# MSPM0C110X register map
Vendor: Texas Instruments; File version: This preliminary header file does not have a version number - build date: 2024-04-30 10:45:50
CPU: CM0 r0p1, little endian, MPU, no FPU, 3 interrupt priority bits
Registers are 32-bit, read-write, reset 0x0 unless marked. A register's access mark holds for its fields unless they carry their own. Offsets are from the block's base; [hi:lo] are bit positions; lines under a group give offsets from that group; {n}, {i} and the like mark numbered series; 'fields as' and 'values as' point back to an identical list; <NAME> marks a mode.

## SYSCTL
Base 0x400AF000
{0x4+0x18*i} SYSCTL_PINCM[{i}] (i=0..0) group
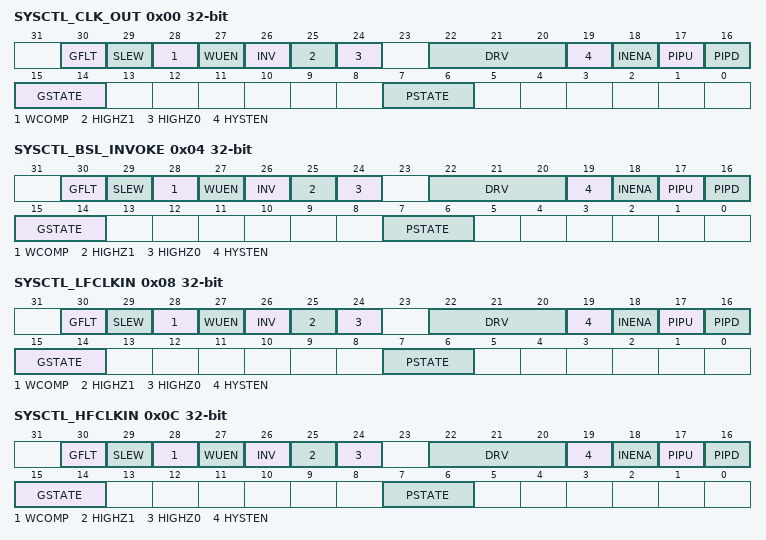
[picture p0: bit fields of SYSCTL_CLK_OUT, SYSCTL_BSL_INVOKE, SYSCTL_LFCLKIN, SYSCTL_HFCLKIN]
  0x00 SYSCTL_CLK_OUT — CLK_OUT
    [30] GFLT — Glitch Filter Enable
      0=DISABLE (No internal glitch filter); 1=ENABLE (Use internal glitch filter)
    [29] SLEW — Reserved Slew Rate Control
      0=DISABLE (No Slew Rate Control); 1=ENABLE (Use Slew Rate Control)
    [28] WCOMP — Wake up compare value
      0=MATCH_ZERO (Match 0 will wake); 1=MATCH_ONE (Match 1 will wake)
    [27] WUEN — Wake up enable
      0=NO_WAKEUP (Wake up not enabled); 1=WAKEUP (Wake up enabled)
    [26] INV — Invert digital input/output relative to peripheral/GPIO
      0=NO_CHNG (Input and output are non-inverted); 1=CHNG (Input and output are inverted)
    [25] HIGHZ1 — High-Z instead of high output
      0=DRV_HIGH (Pin can be driven high); 1=DRV_HIZ (Pin is tri-stated instead of driven high)
    [24] HIGHZ0 — High-Z instead of low output
      0=DRV_LOW (Pin can be driven low); 1=DRV_HIZ (Pin is tri-stated instead of driven low)
    [22:20] DRV — Drive strength options
      0=STRENGTH_0 (Lowest drive strength); {v}=STRENGTH_{v} (Drive strength {v+1}/8) (v=1..6); 7=STRENGTH_7 (Highest drive strength)
    [19] HYSTEN — Hysteresis enable
      0=DIS_HYST (No hysteresis); 1=EN_HYST (Hysteresis on)
    [18] INENA — Input enable
      0=INP_DISABLE (Inputs 0 to connected core); 1=INP_ENABLE (Inputs IO pad value to connected core)
    [17] PIPU — Pull up enable
      0=NO_PULL_UP; 1=PULL_UP
    [16] PIPD — Pull down enable
      0=NO_PULL_DOWN; 1=PULL_DOWN
    [15:14] GSTATE — GPIO Channel State
      0=UNASSIGNED (G-Channel is in Unassigned State); 1=HANDOVER (G-Channel is in Handover State); 2=CONC_NOT_LOCKED (G-Channel is in Connected State and not Locked (That is F field is allowed to change without going back through Unassigned state)); 3=CONC_LOCKED (G-Channel is in Connected State and Locked (That is F field is not allowed to change to a different non-Zero value until both G and P channels go to Unassigned))
    [7:6] PSTATE — Peripheral-Analog Channel State
      0=UNASSIGNED (P-Channel is in Unassigned State); 1=HANDOVER (P-Channel is in Handover State); 2=CONC_NOT_LOCKED (P-Channel is in Connected State and not Locked (That is F field is allowed to change without going back through Unassigned state)); 3=CONC_LOCKED (P-Channel is in Connected State and Locked (That is F field is not allowed to change to a different non-Zero value until both G and P channels go to Unassigned))
  0x04 SYSCTL_BSL_INVOKE — BSL Invoke
    fields as SYSCTL_PINCM[0].SYSCTL_CLK_OUT
  0x08 SYSCTL_LFCLKIN — BSL Invoke
    fields as SYSCTL_PINCM[0].SYSCTL_CLK_OUT
  0x0C SYSCTL_HFCLKIN — BSL Invoke
    fields as SYSCTL_PINCM[0].SYSCTL_CLK_OUT
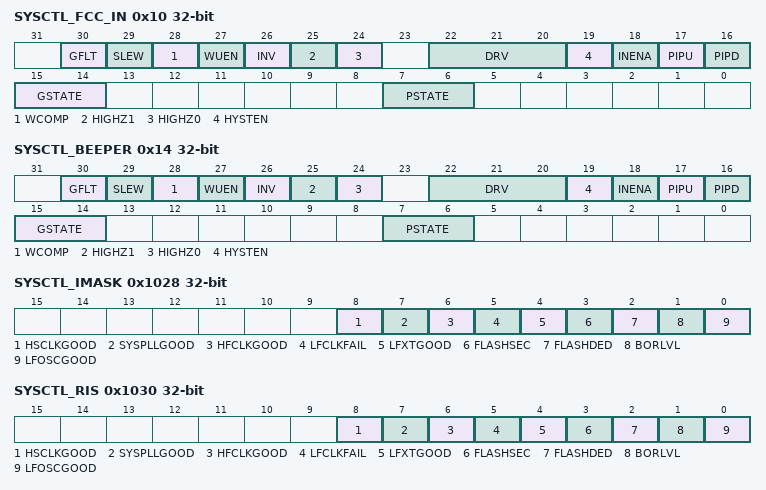
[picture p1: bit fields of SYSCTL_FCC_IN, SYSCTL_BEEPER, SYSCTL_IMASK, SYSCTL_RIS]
  0x10 SYSCTL_FCC_IN — BSL Invoke
    fields as SYSCTL_PINCM[0].SYSCTL_CLK_OUT
  0x14 SYSCTL_BEEPER — BEEPER
    fields as SYSCTL_PINCM[0].SYSCTL_CLK_OUT
0x1020 SYSCTL_IIDX ro — Event IIDX
  [3:0] STAT — Interrupt Index Register -- Read Only
    0=NO_INTR (No Interrupt); 1=LFOSCGOOD; 2=BORLVL; 3=FLASHDED; 4=FLASHSEC; 5=LFXTGOOD; 6=LFCLKFAIL; 7=HFCLKGOOD; 8=SYSPLLGOOD; 9=HSCLKGOOD
0x1028 SYSCTL_IMASK — Event IMASK
  [all] fields
    0=DISABLE; 1=ENABLE
  [8] HSCLKGOOD
  [7] SYSPLLGOOD
  [6] HFCLKGOOD
  [5] LFCLKFAIL — LFXT-EXLF Monitor Fail
  [4] LFXTGOOD
  [3] FLASHSEC — Flash Single Error Correct
  [2] FLASHDED — Flash Double Error Detect
  [1] BORLVL — BOR Level Indicator
  [0] LFOSCGOOD
0x1030 SYSCTL_RIS ro — Event RIS
  [all] fields
    0=FALSE; 1=TRUE
  [8] HSCLKGOOD
  [7] SYSPLLGOOD
  [6] HFCLKGOOD
  [5] LFCLKFAIL — LFXT-EXLF Monitor Fail
  [4] LFXTGOOD
  [3] FLASHSEC — Flash Single Error Correct
  [2] FLASHDED — Flash Double Error Detect
  [1] BORLVL — BOR Level Indicator
  [0] LFOSCGOOD
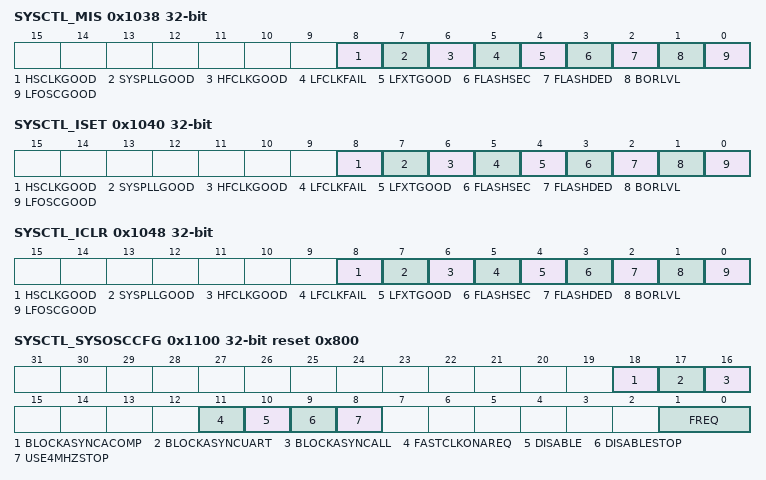
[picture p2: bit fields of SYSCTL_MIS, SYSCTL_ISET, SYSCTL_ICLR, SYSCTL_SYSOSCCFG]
0x1038 SYSCTL_MIS ro — Event MIS
  fields as SYSCTL_RIS
0x1040 SYSCTL_ISET wo — Event ISET
  [all] fields
    0=NO_EFFECT; 1=SET
  [8] HSCLKGOOD
  [7] SYSPLLGOOD
  [6] HFCLKGOOD
  [5] LFCLKFAIL — LFXT-EXLF Monitor Fail
  [4] LFXTGOOD
  [3] FLASHSEC — Flash Single Error Correct
  [2] FLASHDED — Flash Double Error Detect
  [1] BORLVL — BOR Level Indicator
  [0] LFOSCGOOD
0x1048 SYSCTL_ICLR wo — Event ICLR
  [all] fields
    0=NO_EFFECT; 1=CLR
  [8] HSCLKGOOD
  [7] SYSPLLGOOD
  [6] HFCLKGOOD
  [5] LFCLKFAIL — LFXT-EXLF Monitor Fail
  [4] LFXTGOOD
  [3] FLASHSEC — Flash Single Error Correct
  [2] FLASHDED — Flash Double Error Detect
  [1] BORLVL — BOR Level Indicator
  [0] LFOSCGOOD
0x1100 SYSCTL_SYSOSCCFG reset 0x800 — SYSOSC Configuration
  [18] BLOCKASYNCACOMP — Block all ACOMP async requests from enabling SYSOSC via hardware, ie keep running from LFCLK if UART is requester
    0=DISABLE; 1=ENABLE
  [17] BLOCKASYNCUART — Block all UART async requests from enabling SYSOSC via hardware, ie keep running from LFCLK if UART is requester
    0=DISABLE; 1=ENABLE
  [16] BLOCKASYNCALL — Block all async requests from enabling SYSOSC via hardware, ie keep running from LFCLK
    0=DISABLE; 1=ENABLE
  [11] FASTCLKONAREQ — Force BASE (or higher) Freqency when there is async sysosc request 0: Leave as current frequency 1: Force BASE or current that is higher
    0=DISABLE; 1=ENABLE
  [10] DISABLE — Disable SYSOSC to run all power modes with LFCLK
    0=DISABLE; 1=ENABLE
  [9] DISABLESTOP — Disable SYSOSC when in STOP mode to allow STOP with LFCLK
    0=DISABLE; 1=ENABLE
  [8] USE4MHZSTOP — SYOSC Frequency during stop 0: 32M 1: 4M
    0=DISABLE; 1=ENABLE
  [1:0] FREQ — Freq Target: 0: BASE 1: 4M 2: USER 3: Reserved for Turbo 48MHz
    0=SYSOSCBASE; 1=SYSOSC4M; 2=SYSOSCUSER; 3=SYSOSCTURBO
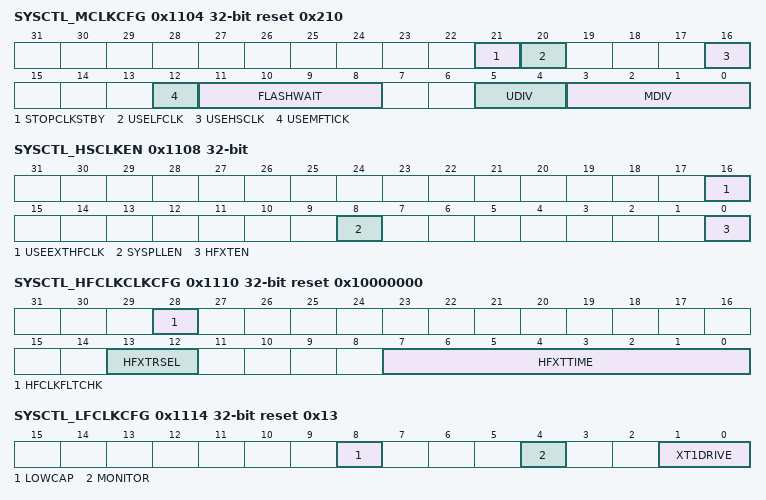
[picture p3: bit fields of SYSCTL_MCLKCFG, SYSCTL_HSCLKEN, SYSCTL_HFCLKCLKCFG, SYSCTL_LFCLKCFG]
0x1104 SYSCTL_MCLKCFG reset 0x210 — Configuration related to MCLK
  [21] STOPCLKSTBY — STOP ULPCLK Root during STANDBY, Only wake on ASYNC IO Events
    0=DISABLE; 1=ENABLE
  [20] USELFCLK — Low Frequency Clock Selected for MCLK
    0=DISABLE; 1=ENABLE
  [16] USEHSCLK — High Speed Clock Selected for MCLK (HFCLK, PLL,...)
    0=DISABLE; 1=ENABLE
  [12] USEMFTICK — USE the MFTICK feature (this will limit MDIV options)
    0=DISABLE; 1=ENABLE
  [11:8] FLASHWAIT — Flash wait states when using a high speed clock source - HFCLK or PLL
  [5:4] UDIV — UDIV Divider 0: MCLK 1: MCLK div 22: MCLK div 3 when USEHSCLK is TRUE
    0=NODIVIDE (ULPCLK is MCLK); 1=DIVIDE2 (ULPCLK is MCLK div 2)
  [3:0] MDIV — MDIV Divider 1..16 when RUN-SLEEP
0x1108 SYSCTL_HSCLKEN — High Speed Clock Configuration
  [all] fields
    0=DISABLE; 1=ENABLE
  [16] USEEXTHFCLK — Use External Pin as High Frequency Oscillator Source(HFCLK)
  [8] SYSPLLEN — Enable the SYSTEM PLL
  [0] HFXTEN — Enable the HFXT Crystal
0x110C SYSCTL_HSCLKCFG — High Speed Clock Configuration
  [0] HSCLKSEL — High Speed Clock Source 0: SYSPLL, 1:HFCLKCLK
    0=SYSPLL; 1=HFCLKCLK
0x1110 SYSCTL_HFCLKCLKCFG reset 0x10000000 — High Frequency OSC Clock Configuration
  [28] HFCLKFLTCHK — Check for stuck fault on HFCLK related pins
    0=DISABLE; 1=ENABLE
  [13:12] HFXTRSEL — HFXT Range Select
  [7:0] HFXTTIME — HFXT startup time in 64 usec resolution
0x1114 SYSCTL_LFCLKCFG reset 0x13 — Low Frequency External Clock Configuration
  [8] LOWCAP — Can be enabled if CAP is less than 3pf for reduced power
    0=DISABLE; 1=ENABLE
  [4] MONITOR — Use Monitor for LFXT, EXLF failure
    0=DISABLE; 1=ENABLE
  [1:0] XT1DRIVE — Drive strength and power consumption option
    0=LOWESTDRV (Lowest Drive and Current); 1=LOWERDRV (Lower Drive and Current); 2=HIGHERDRV (Higher Drive and Current); 3=HIGHESTDRV (Highest Drive and Current)
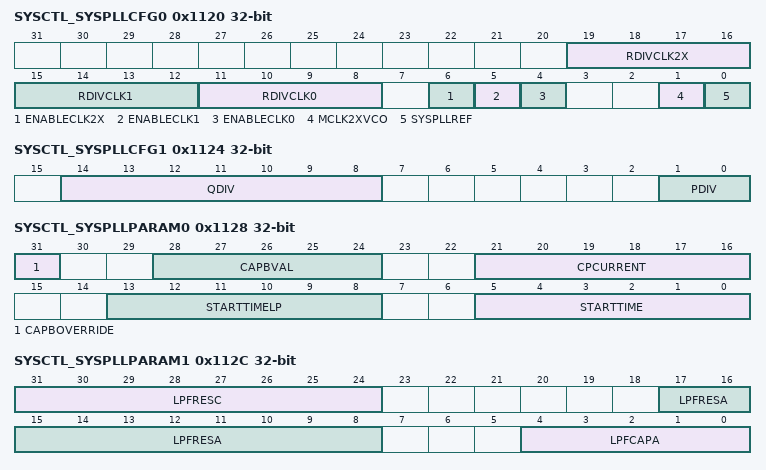
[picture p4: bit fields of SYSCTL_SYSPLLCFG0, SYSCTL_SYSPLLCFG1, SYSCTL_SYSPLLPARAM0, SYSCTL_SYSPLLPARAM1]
0x1120 SYSCTL_SYSPLLCFG0 — System PLL Configuration 0 MMR
  [19:16] RDIVCLK2X — Final Divider for CLK2X Output 1-16
  [15:12] RDIVCLK1 — Final Divider for CLK1 Output 1-16
  [11:8] RDIVCLK0 — Final Divider for CLK0 Output 1-16
  [6] ENABLECLK2X — PLL CLK2X Output enabled
    0=DISABLE; 1=ENABLE
  [5] ENABLECLK1 — PLL CLK1 Output enabled
    0=DISABLE; 1=ENABLE
  [4] ENABLECLK0 — PLL CLK0 Output enabled
    0=DISABLE; 1=ENABLE
  [1] MCLK2XVCO — Use PLL CLK2X PATH as source for MCLK
    0=DISABLE; 1=ENABLE
  [0] SYSPLLREF — System PLL Reference Clock Source 0: SYSOSC, 1:HFCLK
    0=SYSOSC; 1=HFCLK
0x1124 SYSCTL_SYSPLLCFG1 — System PLL Configuration 1 MMR
  [14:8] QDIV — PLL Feedback Clock Divider 1-127 by 1
  [1:0] PDIV — PLL Reference Clock Divider 1,2,4,8
    0=REFDIV1; 1=REFDIV2; 2=REFDIV4; 3=REFDIV8
0x1128 SYSCTL_SYSPLLPARAM0 — System PLL Paramater 0 MMR --- Data from Flash Table Lookup
  [31] CAPBOVERRIDE — Override Enable For Cap B
    0=DISABLE; 1=ENABLE
  [28:24] CAPBVAL — Override Value for Cap B
  [21:16] CPCURRENT — Charge Pump Current
  [13:8] STARTTIMELP — Startup time from Low Power Exit to Locked Clock in resolution of 1usec
  [5:0] STARTTIME — Startup time from Enable to Locked Clock in resolution of 1usec
0x112C SYSCTL_SYSPLLPARAM1 — System PLL Paramater 1 MMR --- Data from Flash Table Lookup
  [31:24] LPFRESC — Loop Filter Res C
  [17:8] LPFRESA — Loop Filter Res A
  [4:0] LPFCAPA — Loop Filter Cap A
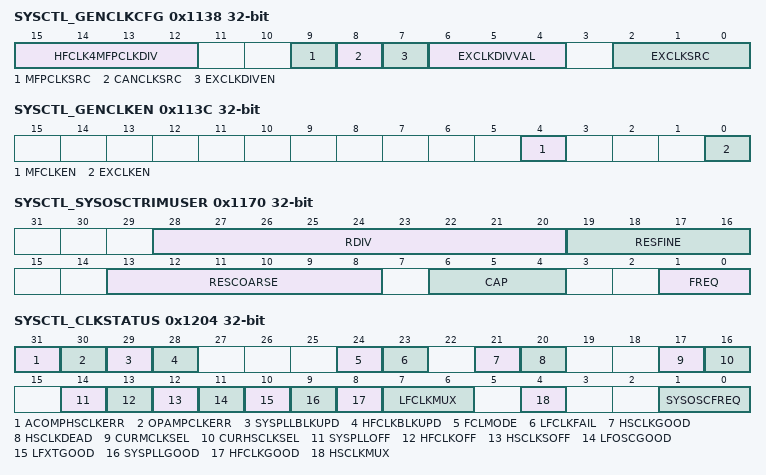
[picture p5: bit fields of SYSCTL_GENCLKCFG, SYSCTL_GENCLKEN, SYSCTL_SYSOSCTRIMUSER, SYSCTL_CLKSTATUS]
0x1138 SYSCTL_GENCLKCFG — General Clock Configuration
  [15:12] HFCLK4MFPCLKDIV — HFCLK Divider 1..16
  [9] MFPCLKSRC — Source for MFPCLK Clock
    0=SYSOSC; 1=HFCLK
  [8] CANCLKSRC — Source for CAN Clock
    0=HFCLK; 1=SYSPLLOUT1
  [7] EXCLKDIVEN — 1: Enable divide 0: Pass Src Clock Through
    0=PASSTHRU; 1=ENABLE
  [6:4] EXCLKDIVVAL
    0=DIV2; 1=DIV4; 2=DIV6; 3=DIV8; 4=DIV10; 5=DIV12; 6=DIV14; 7=DIV16
  [2:0] EXCLKSRC — External Clock Source Select
    0=SYSOSC; 1=ULPCLK (NOTE: This must be divided in post divider); 2=LFCLK; 3=MFCLK (NOTE: This must be divided in post divider); 4=HFCLK; 5=SYSPLLOUT1 (NOTE: Must be 48MHz or below)
0x113C SYSCTL_GENCLKEN — General Clock Enables
  [4] MFCLKEN — Enable the MFCLK
    0=DISABLE; 1=ENABLE
  [0] EXCLKEN — Enable the External Clock Output
    0=DISABLE; 1=ENABLE
0x1140 SYSCTL_PMODECFG — Power Mode Configurations
  [1:0] DSLEEP — Action to be taken on DEEPSLEEP 0: STOP, 1:STANDBY, 2: SHUTDOWN 3: Reserved
    0=STOP; 1=STANDBY; 2=SHUTDOWN
0x1168 SYSCTL_SOCLOCK_FLBANKSWAP — Flash Bank Swap
  [0] USEUPPER ro — 1: SWAP upper banks to lower 0: Normal Memory Map
    0=DISABLE; 1=ENABLE
0x1170 SYSCTL_SYSOSCTRIMUSER — SYSOSC Trim Values specified by user
  [28:20] RDIV — FCL RDIV TRIM - Changes per frequency target
  [19:16] RESFINE — Resister Coarse TRIM - Changes per frequency target
  [13:8] RESCOARSE — Resister Coarse TRIM - Changes per frequency target
  [6:4] CAP — CAP TRIM - Changes per frequency target
  [1:0] FREQ — Freq Target: 0: NOT VALID TRIM 1: 16M 2: 24M 3: Reserved
    1=SYSOSC16M; 2=SYSOSC24M
0x1178 SYSCTL_SYSMEMWEPROT — SRAM Write Protect
0x1180 SYSCTL_SYSTEMCFG — SRAM Write Protect
  [0] FLASHECCRSTDIS — 0: Flash ECC Double Error will issue System Reset (default) 1: Reset is disable but sysstatus will be provided
    0=FALSE; 1=TRUE
0x1200 SYSCTL_WRITELOCK — SYSOSC Trim Values specified by user
  [0] ACTIVE — LOCK configuration MMRs from write
    0=DISABLE (Disallow Writes to Lockable MMRs); 1=ENABLE (Allow Writes to Lockable MMRs)
0x1204 SYSCTL_CLKSTATUS ro — Useful debug status of clock selections
  [31] ACOMPHSCLKERR — Error with Anacomp High Speed CP Clock Generation - SYSOSC must not run at 4MHz
    0=FALSE; 1=TRUE
  [30] OPAMPCLKERR — Error with OPAMP Clock Generation
    0=FALSE; 1=TRUE
  [29] SYSPLLBLKUPD — Writes to SYSPLLCFG0-1, SYSPLLPARAM0-1 are blocked
    0=FALSE; 1=TRUE
  [28] HFCLKBLKUPD — Writes to HFCLKCLKCFG are blocked
    0=FALSE; 1=TRUE
  [24] FCLMODE — SYSOSC FCL MODE ON
    0=DISABLED; 1=ENABLED
  [23] LFCLKFAIL — Clock Fail for LFXT or EXLF clock source
    0=FALSE; 1=TRUE
  [21] HSCLKGOOD — High Speed Clock Good
    0=FALSE; 1=TRUE
  [20] HSCLKDEAD — High Speed Clock Stuck Fault
    0=FALSE; 1=TRUE
  [17] CURMCLKSEL — MCLK Clock Source 0: NOT LFCLK, 1:LFCLK
    0=NOTLFCLK; 1=LFCLK
  [16] CURHSCLKSEL — High Speed Clock Source 0: SYSPLL, 1:HFCLK
    0=SYSPLL; 1=HFCLK
  [14] SYSPLLOFF — SYSPLL is OFF or DEAD
    0=FALSE; 1=TRUE
  [13] HFCLKOFF — HFCLKs is OFF or DEAD
    0=FALSE; 1=TRUE
  [12] HSCLKSOFF — All PLLs, HFCLKs are OFF or DEAD
    0=FALSE; 1=TRUE
  [11] LFOSCGOOD — LFOSC is Valid
    0=FALSE; 1=TRUE
  [10] LFXTGOOD — LFXT is Valid
    0=FALSE; 1=TRUE
  [9] SYSPLLGOOD — SYSTEM PLL ON
    0=FALSE; 1=TRUE
  [8] HFCLKGOOD — High Frequency Clock ON
    0=FALSE; 1=TRUE
  [7:6] LFCLKMUX — Low Frequency Clock Selected
    0=LFOSC (Internal LFOSC); 1=LFXT (LF Crystal); 2=EXLF (External LFCLK IN)
  [4] HSCLKMUX — High Speed Clock Selected for MCLK (HFCLK, PLL,...)
    0=SYSOSC; 1=HSCLK
  [1:0] SYSOSCFREQ — Current SYSOSC frequency setting
    0=SYSOSC32M; 1=SYSOSC4M; 2=SYSOSCUSER; 3=SYSOSCTURBO
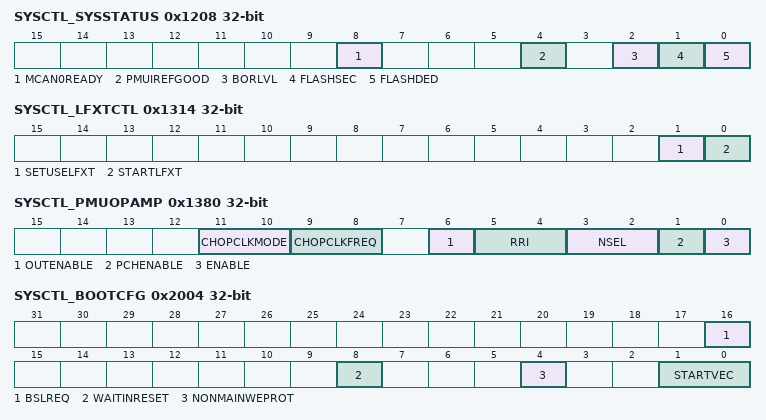
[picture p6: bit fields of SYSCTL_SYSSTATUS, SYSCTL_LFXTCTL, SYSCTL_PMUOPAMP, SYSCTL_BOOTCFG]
0x1208 SYSCTL_SYSSTATUS ro — Useful System Status Data
  [all] fields
    0=FALSE; 1=TRUE
  [8] MCAN0READY
  [4] PMUIREFGOOD — PMU IFREF GOOD
  [2] BORLVL — BOR LEVEL STATUS Indicator
  [1] FLASHSEC — Single Error Correction on Flash
  [0] FLASHDED — Double Error Detect on Flash
0x1300 SYSCTL_RESETLEVEL — Reset Level for Application Reset Command
  [1:0] LEVEL — Reset Level 0: CPU plus peripherals, 1: BOR level reset to BOOTCODE, 2: Do CPU plus Peripheral reset then BOOTLOADER, 3: Full Power On Reset -- vcore disabled
    0=CPU (Reset CPU plus peripherals only); 1=BOOT (Reset Main Infrastructure including TRIM); 2=BOOTLOADER (Reset Main Infrastructure and Run BOOTLOADER); 3=POR (Reset as a Power On Reset)
0x1304 SYSCTL_RESETCMD wo — Execute Reset Command
  [0] GO — Execute Reset defined in RESETLEVEL
    1=TRUE (Issue Reset)
0x1308 SYSCTL_BORTHRESHOLD — BOR Threshold Level
  [1:0] LEVEL — BOR Threshold Level 0: Full Re-boot This level is always enforced regardless of MMR seting 1-3: Generates interrupt
    0=BORMIN (Minimum allowed threshold - will force a re-boot); 1=BORLEVEL1 (BOR Level 1 -- Generates an Interupt); 2=BORLEVEL2 (BOR Level 2 -- Generates an Interupt); 3=BORLEVEL3 (BOR Level 3 -- Generates an Interupt)
0x1310 SYSCTL_SYSOSCFCLCTL wo — SYSOSC Frequency Control Loop with External Resistor
  [0] SETUSEFCL — Use Freq Control Loop
    1=TRUE (Set FCL Control)
0x1314 SYSCTL_LFXTCTL wo — LFXT Control -- Only BOR Level Reset will clear
  [1] SETUSELFXT — Use LFXT
    0=FALSE; 1=TRUE (Use LFXT as 32KHz source)
  [0] STARTLFXT
    0=FALSE; 1=TRUE (Start LFXT)
0x1318 SYSCTL_EXLFCTL wo — EX LF Control -- Only BOR Level Reset will clear
  [2] SETUSEEXLF — Use external LF CLK IN
    0=FALSE; 1=TRUE (Use External LF source)
0x131C SYSCTL_SHDNIOREL wo — Shutdown IO Release Command
  [0] RELEASE — Release IO after Shutdown
    1=TRUE (Release IO after SHUTDOWN Exit)
0x1320 SYSCTL_EXRSTPIN wo — Disable use of external Reset Pin
  [2] DISABLE — Disable External Reset
    0=FALSE; 1=TRUE (Disable External Reset)
0x1324 SYSCTL_SYSSTATUSCLR wo — Clear sticky bits of SYSSTATUS
  [2] ALLECC — Clear ALL ECC related SYSSTATUS indicators
    1=CLEAR (Clear ECC state)
0x1328 SYSCTL_SWDCFG wo — Disable SWD
  [2] DISABLE
    0=FALSE; 1=TRUE (Disable SWD)
0x1380 SYSCTL_PMUOPAMP — PMU OPAMP Control
  [11:10] CHOPCLKMODE — CHOP Clock Mode
    0=CHOPDISABLED; 1=REGCHOP (Regular Chop); 2=ADCASSIST (ADC Assisted Chop)
  [9:8] CHOPCLKFREQ — CHOP Clock frequency select
    0=CLK16KHZ; 1=CLK8KHZ; 2=CLK4KHZ; 3=CLK2KHZ
  [6] OUTENABLE — Output To Pad Enable
    0=FALSE; 1=TRUE
  [5:4] RRI — Rail to Rail Input Mode Select
    0=MODE0 (select PMOS input pairs mode); 1=MODE1 (select NMOS input pairs mode); 2=MODE2 (select rail to rail mode); 3=MODE3 (select sample channel 0)
  [3:2] NSEL — Negative Channel Input Select
    0=SEL0 (Select buf output pad as input); 1=SEL1 (select unbuf output pad as input); 2=SEL2 (select internal buffer output as input); 3=SEL3 (no channel selected)
  [1] PCHENABLE — Positive Channel Input Enable
    0=FALSE; 1=TRUE
  [0] ENABLE — Enable PMU OPAMP
    0=FALSE; 1=TRUE
{0x1400+4i} SYSCTL_SHUTDNSTORE{i} (i=0..3) — Shutdown Storage Byte {i}
  [7:0] DATA
0x2000 SYSCTL_LIFECYCLE reset 0x55 — Device Lifecycle
  [7:0] VALUE — Device Lifecycle set by BOOTCODE READY=0x69(105), ATTEST=0x55(85), PREPROBE=0x96(150)
    85=ATTEST (Device in TI Test Mode); 105=READY (Device in Product Mode); 150=PREPROBE (Device in Pre Probe State)
0x2004 SYSCTL_BOOTCFG — Configuration of CPURESET Vector
  [16] BSLREQ — 0: Full Bringup 1: TRIM already loaded, requesting BSL
  [8] WAITINRESET — 0: Normal operation 1: CPU held in reset for debugger to control release
  [4] NONMAINWEPROT — 0: NonMain Flash area can be modified 1: Program-Erase will be ignored
  [1:0] STARTVEC — Reset Vector target location at next reset
    0=BOOTCODE (Reset to BOOTCODE); 1=BOOTLOADER (Reset to BOOTLOADER); 2=APPFLASH (Reset to FLASH 0x0); 3=APPSRAM (Reset to SRAM 0x0)
0x2008 SYSCTL_BOOTDONE wo — BOOTCODE PASS
  [0] PASS — BOOTCODE writes 1 for PASS, left unwritten a timeout will occur if not blocked
    1=TRUE (BOOTCODE PASS)
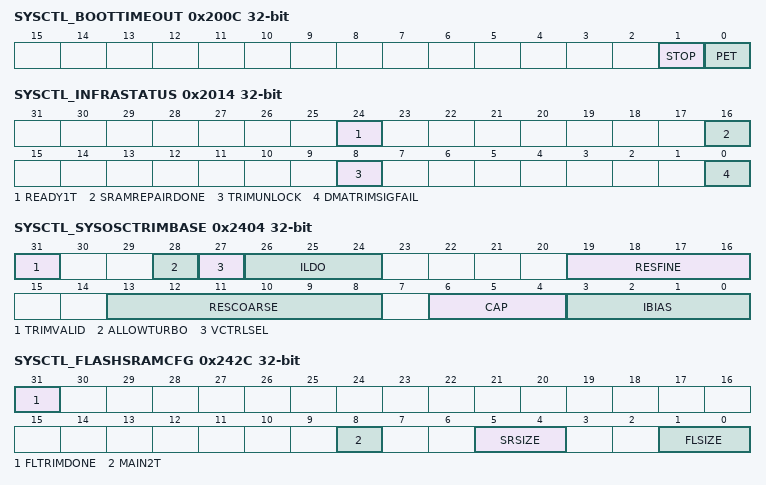
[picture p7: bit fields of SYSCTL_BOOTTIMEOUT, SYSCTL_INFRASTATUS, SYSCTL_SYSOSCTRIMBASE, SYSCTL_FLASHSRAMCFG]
0x200C SYSCTL_BOOTTIMEOUT wo — BOOT TIMEOUT Control
  [1] STOP — BOOTCODE writes 1 for STOPPING BOOT TIMEOUT Counter
    1=TRUE (STOP Bootcode Timeout Counter)
  [0] PET — BOOTCODE writes 1 for reloading BOOT TIMEOUT Counter
    1=TRUE (Restart Bootcode Timeout Counter)
0x2010 SYSCTL_BCTRIMUNLOCK wo — BootCode TRIM Unlock
0x2014 SYSCTL_INFRASTATUS ro — Infrastructure Status
  [24] READY1T — Flash 1T Read mode is available
  [16] SRAMREPAIRDONE — SRAM repair is completed or not supported on this SOC
  [8] TRIMUNLOCK — TRIM MMRs are UNLOCKED
  [0] DMATRIMSIGFAIL — DMA TRIM signiture fail
0x2018 SYSCTL_BOOTDIAG — 8 bit boot diagnostic to Debugss
  [7:0] DATA
0x201C SYSCTL_INFRASTATUS1 ro — Infrastructure Status 2
  [0] CRPAD — Customer Return Pad
0x2020 SYSCTL_FWEPROTMAINA — 1 Sector Write-Erase per bit starting at address 0x0 of flash
0x2024 SYSCTL_FWEPROTMAINB0 — 8xSector Write-Erase per bit starting at address 0x0 of flash
  [15:0] DATA — 8xSector Write Erase protection 1: prohibits write-erase, 0: allows
0x2040 SYSCTL_JTAGUSERCODE — JTAG USERCODE
0x2400 SYSCTL_DMATRIMUNLOCK wo — DMA TRIM Unlock
0x2404 SYSCTL_SYSOSCTRIMBASE — SYSOSC Trim Values for frequency when change from disable to enable, generally 32MHz
  [31] TRIMVALID — TRIM Data Valid- used to trigger FSM
  [28] ALLOWTURBO — SYSOSC 48MHz (TURBO) TI trim can be used
  [27] VCTRLSEL — VCTRL SEL used potentially needed for FCL mode. Default 0
  [26:24] ILDO — ILDO TRIM -- Only 1 value, Not frequency dependent
  [19:16] RESFINE — Resister Coarse TRIM - Changes per frequency target
  [13:8] RESCOARSE — Resister Coarse TRIM - Changes per frequency target
  [6:4] CAP — CAP TRIM - Changes per frequency target
  [3:0] IBIAS — IBIAS TRIM - Only 1 value, not frequency dependent
{0x2408+4i} SYSCTL_PMUTRIM{i} (i=0..5) — PMU TRIM {i}
  [9:0] DATA — SEE PMU definition for usage
0x2420 SYSCTL_FLASHPUMPTRIM — Flash Pump TRIM-CFG
0x2424 SYSCTL_FLASHBANK0TRIM — $btname TRIM-CFG
0x2428 SYSCTL_FLASHBANK0REPAIR — $brname Flash Repair
  [13:0] DATA — Repair Bits
0x242C SYSCTL_FLASHSRAMCFG — Flash and SRAM Configuration
  [31] FLTRIMDONE — 1: Flash TRIM bits loaded 0: TRIM unwritten
  [8] MAIN2T — 1: Main (nonmain) are 2T access 0: Main (nonmain) are 1T access
  [5:4] SRSIZE — SRAM Paper Spin 0: Full size, 1: 1/2, 2: 1/4
  [1:0] FLSIZE — Flash Paper Spin 0: Full size, 1: 1/2, 2: 1/4
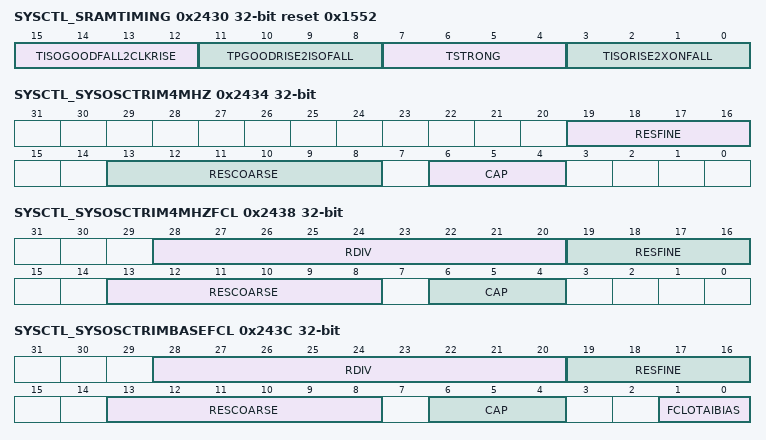
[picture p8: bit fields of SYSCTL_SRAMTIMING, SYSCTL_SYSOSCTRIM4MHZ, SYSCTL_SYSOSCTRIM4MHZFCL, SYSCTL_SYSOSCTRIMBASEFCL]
0x2430 SYSCTL_SRAMTIMING reset 0x1552 — SRAM timing MMR for ESRAM controller, based on 4MHz
  [15:12] TISOGOODFALL2CLKRISE — ISO GOOD FALL to CLKRISE, spec 250ns (boot 500ns)
  [11:8] TPGOODRISE2ISOFALL — PGOOD RISE to ISO FALL, spec 750ns (boot 1500ns)
  [7:4] TSTRONG — Driver Weak to Stong timing, spec 1000ns (boot 1500ns)
  [3:0] TISORISE2XONFALL — ISO Rise to any ON FALL, spec 500ns (boot 750ns)
0x2434 SYSCTL_SYSOSCTRIM4MHZ — SYSOSC Trim Values for 4MHz target
  [19:16] RESFINE — Resister Coarse TRIM - Changes per frequency target
  [13:8] RESCOARSE — Resister Coarse TRIM - Changes per frequency target
  [6:4] CAP — CAP TRIM - Changes per frequency target
0x2438 SYSCTL_SYSOSCTRIM4MHZFCL — SYSOSC Trim Values for 4MHz target with FCL enabled
  [28:20] RDIV — FCL RDIV TRIM - Changes per frequency target
  [19:16] RESFINE — Resister Coarse TRIM - Changes per frequency target
  [13:8] RESCOARSE — Resister Coarse TRIM - Changes per frequency target
  [6:4] CAP — CAP TRIM - Changes per frequency target
0x243C SYSCTL_SYSOSCTRIMBASEFCL — SYSOSC Trim Values for 32MHz target with FCL enabled
  [28:20] RDIV — FCL RDIV TRIM - Changes per frequency target
  [19:16] RESFINE — Resister Fine TRIM - Changes per frequency target
  [13:8] RESCOARSE — Resister Coarse TRIM - Changes per frequency target
  [6:4] CAP — CAP TRIM - Changes per frequency target
  [1:0] FCLOTAIBIAS — FCL IBIAS TRIM, Not frequency dependent
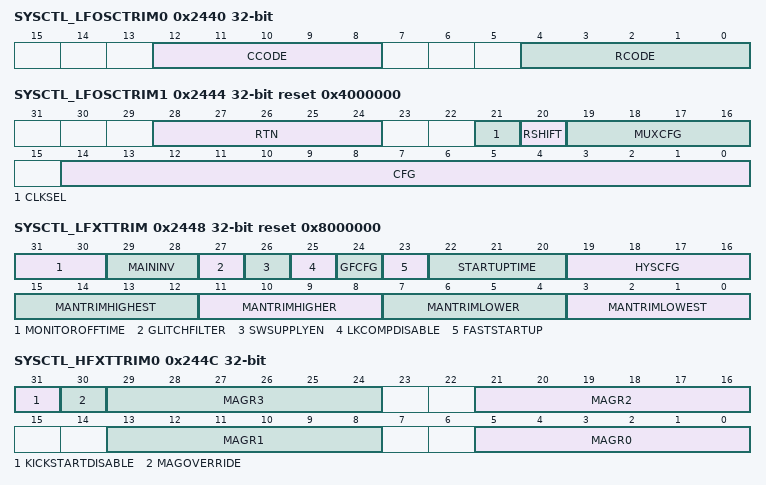
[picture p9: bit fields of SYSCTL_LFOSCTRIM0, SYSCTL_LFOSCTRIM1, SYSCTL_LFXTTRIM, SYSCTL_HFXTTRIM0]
0x2440 SYSCTL_LFOSCTRIM0 — LFOSC TRIM values
  [12:8] CCODE — LFOSC Cap Frequency Trim
  [4:0] RCODE — LFOSC Res Frequency Trim
0x2444 SYSCTL_LFOSCTRIM1 reset 0x4000000 — LFOSC TRIM values
  [28:24] RTN — LFOSC Noise Trim
  [21] CLKSEL — 0: divide LFOSC by 2 to give 32KHz, 1: pass through 64KHz
  [20] RSHIFT — LFOSC RSHIFT Trim
  [19:16] MUXCFG — LFOSC Mux CFG Trim
  [14:0] CFG — LFOSC CFG Trim
0x2448 SYSCTL_LFXTTRIM reset 0x8000000 — LFXT TRIM values
  [31:30] MONITOROFFTIME — XT Monitor Off Time Trim
  [29:28] MAININV — LFXT Main Inverter Strength
  [27] GLITCHFILTER — Glitch Filter Enable
    0=DISABLE; 1=ENABLE
  [26] SWSUPPLYEN — LFXT SW Supply Enable
  [25] LKCOMPDISABLE — LFXT Leakage Comp Disable
  [24] GFCFG — LFXT GFCFG
  [23] FASTSTARTUP — LFXT Fast Startup Select
  [22:20] STARTUPTIME — LFXT Startup Time
  [19:16] HYSCFG — LFXT Hysterisys Config
  [15:12] MANTRIMHIGHEST — LFXT Man Reg Trim Highest Power
  [11:8] MANTRIMHIGHER — LFXT Man Reg Trim Higher Power
  [7:4] MANTRIMLOWER — LFXT Man Reg Trim Lower Power
  [3:0] MANTRIMLOWEST — LFXT Man Reg Trim Lowest Power
0x244C SYSCTL_HFXTTRIM0 — HFXT TRIM and Override
  [31] KICKSTARTDISABLE — DISABLE Kickstart
    0=FALSE; 1=TRUE
  [30] MAGOVERRIDE — Use this TRIM value instead of hardwired
    0=DISABLE; 1=ENABLE
  [8n+5:8n] MAGR{n} (n=0..3) — Value for MAG TRIM Range {n}
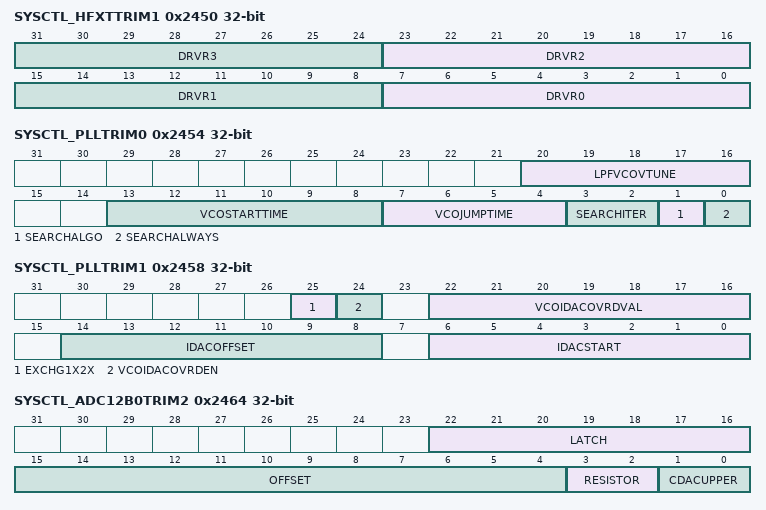
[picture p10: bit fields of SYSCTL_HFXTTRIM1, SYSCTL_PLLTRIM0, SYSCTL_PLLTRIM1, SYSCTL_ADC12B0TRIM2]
0x2450 SYSCTL_HFXTTRIM1 — HFXT TRIM and Override
  [8n+7:8n] DRVR{n} (n=0..3) — Value for DRV TRIM Range {n}
0x2454 SYSCTL_PLLTRIM0 — PLL TRIM and Override
  [20:16] LPFVCOVTUNE — LPF VCOVTUNE NOM Value
  [13:8] VCOSTARTTIME — VCO Start Settling Time in SYSOSC BASE clocks generally 32MHz - this comes before STARTTIME-STARTTIMELP
  [7:4] VCOJUMPTIME — VCO Freq Jump Settling Time
  [3:2] SEARCHITER — Search iterations to perform
    0=OneIteration; 1=TwoIteration; 2=ThreeIteration; 3=FourIteration
  [1] SEARCHALGO — Select Search Mode Algorithm
    0=ALG1; 1=ALG2
  [0] SEARCHALWAYS — Force Freq Search to ALWAYS be performed
    0=DISABLE; 1=ENABLE
0x2458 SYSCTL_PLLTRIM1 — PLL TRIM and Override
  [25] EXCHG1X2X — Exchange 1X and 2X clock paths - Experimental
    0=DISABLE; 1=ENABLE
  [24] VCOIDACOVRDEN — VCO Feq IDAC mcode override enable
    0=DISABLE; 1=ENABLE
  [22:16] VCOIDACOVRDVAL — VCO Feq IDAC mcode override val
  [14:8] IDACOFFSET — IDAC Offset Value
  [6:0] IDACSTART — IDAC Start Value
0x245C SYSCTL_ADC12B0TRIM0 — Bits 31..0 of CDAC
0x2460 SYSCTL_ADC12B0TRIM1 — Bits 63..32 of CDAC
0x2464 SYSCTL_ADC12B0TRIM2 — Bits 65..64 of CDAC, and other ADC12B0 always trims
  [22:16] LATCH — LATCH TRIM
  [15:4] OFFSET — OFFSET TRIM
  [3:2] RESISTOR — RESISTOR TRIM
  [1:0] CDACUPPER — Bits 65..64 of CDAC
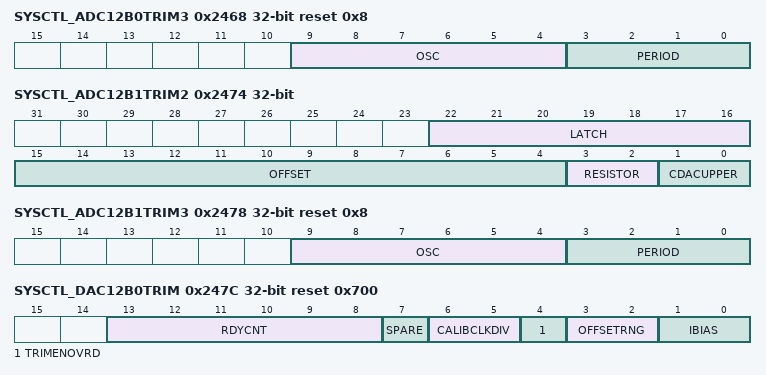
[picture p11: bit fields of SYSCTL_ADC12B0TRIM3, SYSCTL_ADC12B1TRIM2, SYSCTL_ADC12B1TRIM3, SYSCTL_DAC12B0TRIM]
0x2468 SYSCTL_ADC12B0TRIM3 reset 0x8 — Additional ADC trims for 12B 4MSPS
  [9:4] OSC — Oscillator
  [3:0] PERIOD
0x246C SYSCTL_ADC12B1TRIM0 — Bits 31..0 of CDAC
0x2470 SYSCTL_ADC12B1TRIM1 — Bits 63..32 of CDAC
0x2474 SYSCTL_ADC12B1TRIM2 — Bits 65..64 of CDAC, and other ADC12B1 always trims
  fields as SYSCTL_ADC12B0TRIM2
0x2478 SYSCTL_ADC12B1TRIM3 reset 0x8 — Additional ADC trims for 12B 4MSPS
  [9:4] OSC — Oscillator
  [3:0] PERIOD
0x247C SYSCTL_DAC12B0TRIM reset 0x700 — Trims for 12B DAC
  [13:8] RDYCNT — Ready Count in 1 usec resolution
  [7] SPARE — SPARE bit
  [6:5] CALIBCLKDIV — Calibration Clock Divide Conrol
  [4] TRIMENOVRD — Trim Enable Override
  [3:2] OFFSETRNG — Offset Range
  [1:0] IBIAS
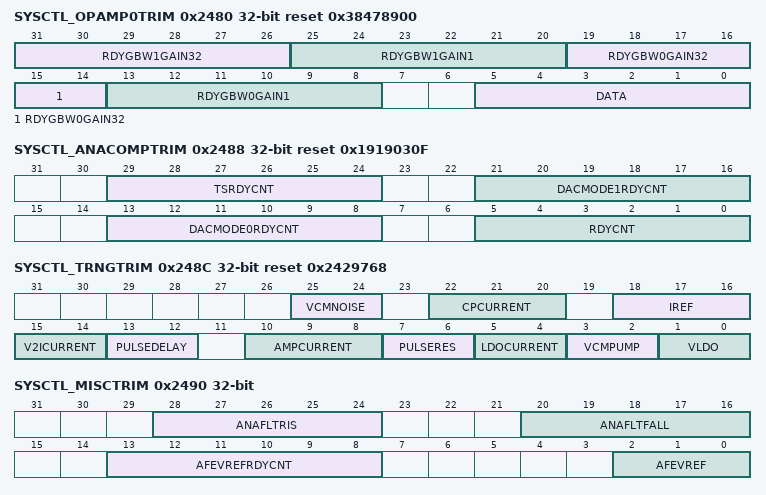
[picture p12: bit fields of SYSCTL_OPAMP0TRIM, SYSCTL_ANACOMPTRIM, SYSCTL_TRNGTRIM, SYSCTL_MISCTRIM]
0x2480 SYSCTL_OPAMP0TRIM reset 0x38478900 — Trims for Opamp0
  [31:26] RDYGBW1GAIN32 — Common Opamp Ready time (in usec)for GBW 1, GAIN 32
  [25:20] RDYGBW1GAIN1 — Common Opamp Ready time (in usec)for GBW 1, GAIN 1
  [19:14] RDYGBW0GAIN32 — Common Opamp Ready time (in usec)for GBW 0, GAIN 32
  [13:8] RDYGBW0GAIN1 — Common Opamp Ready time (in usec) for GBW 0, GAIN 1
  [5:0] DATA — Opamp0 Trim
0x2484 SYSCTL_OPAMP1TRIM — Trims for Opamp1
  [5:0] DATA — Opamp1 Trim
0x2488 SYSCTL_ANACOMPTRIM reset 0x1919030F — Common Trims for Anacomp
  [29:24] TSRDYCNT — TempSense Ready Count in 1 usec resolution
  [21:16] DACMODE1RDYCNT — DAC Ready Count in 1 usec resolution
  [13:8] DACMODE0RDYCNT — DAC Ready Count in 250ns usec resolution
  [5:0] RDYCNT — Ready Count in 1 usec resolution
0x248C SYSCTL_TRNGTRIM reset 0x2429768 — Trim for TRNG
  [25:24] VCMNOISE — TRNG VCM Noise TRIM
  [22:20] CPCURRENT — TRNG CP Current TRIM
  [18:16] IREF — TRNG IREF TRIM
  [15:14] V2ICURRENT — TRNG V2i Current TRIM
  [13:12] PULSEDELAY — TRNG Pulse Delay TRIM
  [10:8] AMPCURRENT — TRNG Amp Current TRIM
  [7:6] PULSERES — TRNG Pulse Res TRIM
  [5:4] LDOCURRENT — TRNG LDO Current TRIM
  [3:2] VCMPUMP — TRNG VCM Pump TRIM
  [1:0] VLDO — TRNG VLDO TRIM
0x2490 SYSCTL_MISCTRIM — Various Small TRIM
  [28:24] ANAFLTRIS — Analog GlitchFilter Rising Trim
  [20:16] ANAFLTFALL — Analog GlitchFilter Falling Trim
  [13:8] AFEVREFRDYCNT — VREF Ready Count Nano is in 1 usec, Micro in 8 usec resolution
  [2:0] AFEVREF — VREF TRIM
0x2494 SYSCTL_PADEXIST0 — PAD Exist for IOMUX
0x2498 SYSCTL_PADEXIST1 — PAD Exist for IOMUX
  [27:0] DATA — Padexists Vector bits
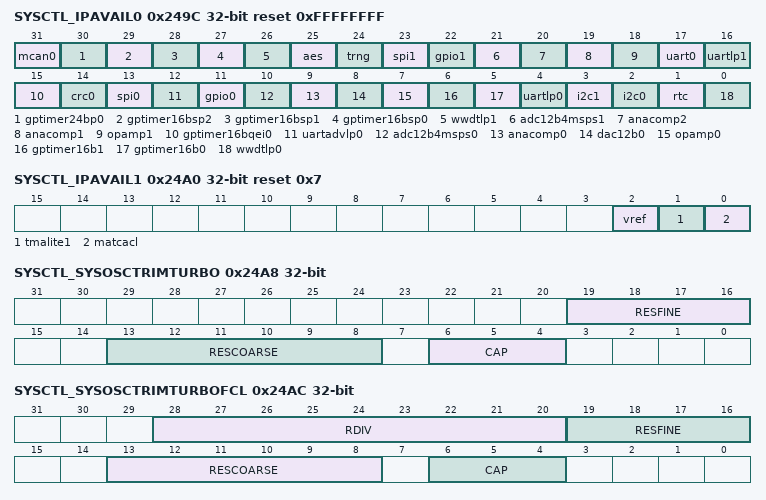
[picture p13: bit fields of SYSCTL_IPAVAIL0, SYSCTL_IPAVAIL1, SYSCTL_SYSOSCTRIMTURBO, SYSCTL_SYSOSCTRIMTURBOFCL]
0x249C SYSCTL_IPAVAIL0 reset 0xFFFFFFFF — IP Available Paper Spin
  [all] fields
    0=NOTAVAILABLE; 1=AVAILABLE
  [31] mcan0 — Peripheral Instance Available
  [30] gptimer24bp0 — Peripheral Instance Available
  [29] gptimer16bsp2 — Peripheral Instance Available
  [28] gptimer16bsp1 — Peripheral Instance Available
  [27] gptimer16bsp0 — Peripheral Instance Available
  [26] wwdtlp1 — Peripheral Instance Available
  [25] aes — Peripheral Instance Available
  [24] trng — Peripheral Instance Available
  [23] spi1 — Peripheral Instance Available
  [22] gpio1 — Peripheral Instance Available
  [21] adc12b4msps1 — Peripheral Instance Available
  [20] anacomp2 — Peripheral Instance Available
  [19] anacomp1 — Peripheral Instance Available
  [18] opamp1 — Peripheral Instance Available
  [17] uart0 — Peripheral Instance Available
  [16] uartlp1 — Peripheral Instance Available
  [15] gptimer16bqei0 — Peripheral Instance Available
  [14] crc0 — Peripheral Instance Available
  [13] spi0 — Peripheral Instance Available
  [12] uartadvlp0 — Peripheral Instance Available
  [11] gpio0 — Peripheral Instance Available
  [10] adc12b4msps0 — Peripheral Instance Available
  [9] anacomp0 — Peripheral Instance Available
  [8] dac12b0 — Peripheral Instance Available
  [7] opamp0 — Peripheral Instance Available
  [6] gptimer16b1 — Peripheral Instance Available
  [5] gptimer16b0 — Peripheral Instance Available
  [4] uartlp0 — Peripheral Instance Available
  [3] i2c1 — Peripheral Instance Available
  [2] i2c0 — Peripheral Instance Available
  [1] rtc — Peripheral Instance Available
  [0] wwdtlp0 — Peripheral Instance Available
0x24A0 SYSCTL_IPAVAIL1 reset 0x7 — IP Available Paper Spin
  [all] fields
    0=NOTAVAILABLE; 1=AVAILABLE
  [2] vref — Peripheral Instance Available
  [1] tmalite1 — Peripheral Instance Available
  [0] matcacl — Peripheral Instance Available
0x24A4 SYSCTL_FUNCPSPIN — Functional Paper Spin Options
  [0] MCANFD — MCAN FD enabled
0x24A8 SYSCTL_SYSOSCTRIMTURBO — SYSOSC Trim Values for R&D Maximum target, likely 48MHz
  fields as SYSCTL_SYSOSCTRIM4MHZ
0x24AC SYSCTL_SYSOSCTRIMTURBOFCL — SYSOSC Trim Values for TURBO target with FCL enabled
  fields as SYSCTL_SYSOSCTRIM4MHZFCL
0x24B0 SYSCTL_TRIMCRC — FINAL 16 bit CRC of the TRIM load
  [15:0] DATA — final 16 bit CRC value
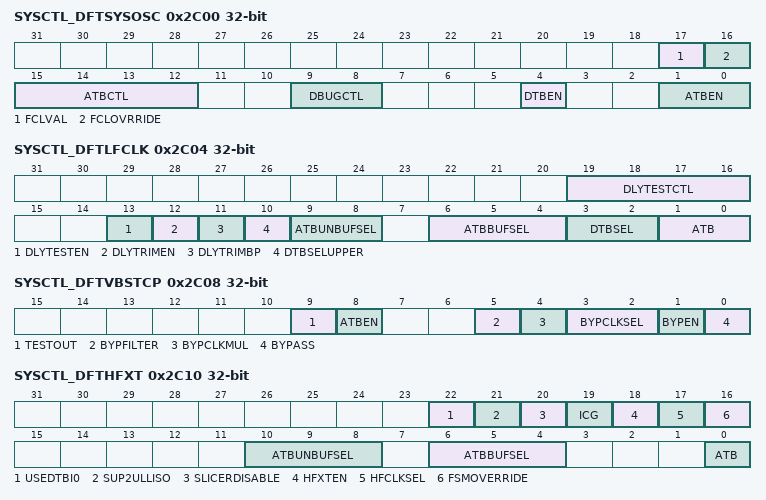
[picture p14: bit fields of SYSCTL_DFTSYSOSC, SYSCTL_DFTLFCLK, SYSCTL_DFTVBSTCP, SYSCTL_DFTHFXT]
0x2C00 SYSCTL_DFTSYSOSC — DFT Control for HFXT
  [17] FCLVAL — Override Value for the FCL Enable into the hard macro
  [16] FCLOVRRIDE — Override the FCL Enable into the hard macro
  [15:12] ATBCTL — ATB Control
  [9:8] DBUGCTL — Debug Control
  [4] DTBEN — Enable DTB Structure
    0=DISABLE; 1=ENABLE
  [1:0] ATBEN — Enable ATB Structure
0x2C04 SYSCTL_DFTLFCLK — DFT Control for LFCLK Hard Macro
  [19:16] DLYTESTCTL — Delay Cell Test CTL
  [13] DLYTESTEN — Delay Cell Test Enable
  [12] DLYTRIMEN — Delay Cell Trim Enable
  [11] DLYTRIMBP — Delay Cell Trim Bypass
  [10] DTBSELUPPER — DTB Select for Upper 4 bits of DTBO[11:0] of hard macro
  [9:8] ATBUNBUFSEL — ATB Buffered Signal Select
  [6:4] ATBBUFSEL — ATB Buffered Signal Select
  [3:2] DTBSEL — DTB Select at hard macro
  [1:0] ATB — Bit1: enables buffered path, Bit0 enables unbuffered path
0x2C08 SYSCTL_DFTVBSTCP — DFT for VBOOST Charge Pump
  [9] TESTOUT — Not conditioned with Bypass. Creates weak test output
    0=DISABLE; 1=ENABLE
  [8] ATBEN — This must be enabled for ATB muxing to operate
    0=DISABLE; 1=ENABLE
  [5] BYPFILTER — No filter makes power up faster
    0=DISABLE; 1=ENABLE
  [4] BYPCLKMUL — Multiply CP clk by 8
    0=DISABLE; 1=ENABLE
  [3:2] BYPCLKSEL — CP Clock Select
    0=CLK4MHZ; 1=CLK1MHZ; 2=CLK32KHZ; 3=DTBI0
  [1] BYPEN — EN to Hard Macro
    0=DISABLE; 1=ENABLE
  [0] BYPASS — BYPASS ALL Normal Control
    0=DISABLE; 1=ENABLE
0x2C10 SYSCTL_DFTHFXT — DFT Control for HFXT
  [22] USEDTBI0 — Use DTBI[0] as the HFCLK output
    0=FALSE; 1=TRUE
  [21] SUP2ULLISO — Isolate HFXT analog from 3V PAD
    0=FALSE; 1=TRUE
  [20] SLICERDISABLE — Turn off slicer
    0=FALSE; 1=TRUE
  [19] ICG — Override Turn HFCLK related ICGs ON qualified with HFCLKSEL
    0=DISABLE; 1=ENABLE
  [18] HFXTEN — Override value for HFXT ENABLE to Hard Macro
    0=DISABLE; 1=ENABLE
  [17] HFCLKSEL — Use External Pin as High Frequency Oscillator Source(HFCLK)
    0=HFXT; 1=EXTHF
  [16] FSMOVERRIDE — Override outputs of HFCLK FSM
    0=DISABLE; 1=ENABLE
  [10:8] ATBUNBUFSEL — ATB Buffered Signal Select
  [6:4] ATBBUFSEL — ATB Buffered Signal Select
  [0] ATB — Enable ATB Structure
    0=DISABLE; 1=ENABLE
0x2C20 SYSCTL_DFTSYSPLL0 — DFT Control for SYSPLL
  [25:20] VCOIDACVAL — Override Value For VCO Freq Idac Code
  [16] VCOIDACOVERRIDE — Override Enable For VCO Freq Idac Code
    0=DISABLE; 1=ENABLE
  [14:12] DTBSEL — DTB Signal Select
  [10:8] ATBUNBUFSEL — ATB UnBuffered Signal Select
  [6:4] ATBBUFSEL — ATB Buffered Signal Select
  [1] DTB — Enable DTB Structure
    0=DISABLE; 1=ENABLE
  [0] ATB — Enable ATB Structure
    0=DISABLE; 1=ENABLE
0x2C24 SYSCTL_DFTSYSPLL1 — DFT Control for SYSPLL
  [9:8] REFCLKSEL — Override value to select Ref Clk
    0=SYSOSC; 1=HFCLK; 2=DTBI0
  [7] ICG2X — Override value to turn PLL ICGCLK2X ON
    0=DISABLE; 1=ENABLE
  [6] ICG1 — Override value to turn PLL ICGCLK1 ON
    0=DISABLE; 1=ENABLE
  [5] ICG0 — Override value to turn PLL ICGCLK0 ON
    0=DISABLE; 1=ENABLE
  [4] PDISO — Assert ISO PD to the hard macro
    0=DEASSERT; 1=ASSERT
  [3] PDRST — Assert RST PD to the hard macro
    0=DEASSERT; 1=ASSERT
  [2] ONDOMAINRST — Assert ONDOMAIN RST to the hard macro
    0=DEASSERT; 1=ASSERT
  [1] PLLEN — Override value for PLL ENABLE to PLL
    0=DISABLE; 1=ENABLE
  [0] FSMOVERRIDE — Override outputs of PLL FSM
    0=DISABLE; 1=ENABLE
0x2C40 SYSCTL_DFTPMUATB — DFT Control for PMU ATB
  [21] UNBUFOUTSWEN
  [20] BUFOUTSWEN
  [19] UBUF2BUFPADEN
  [18] UBUF2BUFEN
  [17] UBUFMUXSEL
  [16] BUFMUXSEL
  [13:12] BUFFERFB
  [10:8] BUFFERMDSEL
  [5] BUFFEREN
  [4] BYPASSSWEN
  [3] SENSEMUXSEL
  [2] SENSEEN
  [1] UBUFEN — ATB UnBuffered Output Enable
  [0] BUFEN — ATB Buffered Output Enable
0x2C44 SYSCTL_DFTPMUCTL — DFT Control for PMU CTL
  [26:24] DTBOSEL
  [22] PARDIS
  [21] PARBYPASS
  [20] DFTPORREQ
  [19] LDOCOMPEN
  [18] LDODISLDO
  [17] LDOENCLAMP
  [16] LDODISPD
  [15] BORDISRST
  [14] BORDISHYS
  [13] BORCTOPFLIP
  [12] BORRDIVPD
  [11] REFEXTBGSEL
  [10] REFCHOPCFG
  [9:6] PMUUBUFCTRL
  [5:2] PMUBUFCTRL
  [1] PMUUBUFEN — ATB UnBuffered Output Enable
  [0] PMUBUFEN — ATB Buffered Output Enable
0x2C48 SYSCTL_DFTPMULPM — DFT Control for PMU LPM
  [5] CPEN, [4] LOADRNG, [3] SMPLEN, [2] SMPL, [1] MODE, [0] OVRDEN
0x2C60 SYSCTL_DFTPMCU — Overall PMCU DFT Controls
  [8] EXTCLKOVRD — External Clock Override for DFT SEL
  [7:4] EXTCLKSEL — External Clock DFT Selections
  [3:0] DTBOSEL — Major DTB Output Select
0x3000 SYSCTL_FWEPROTMAIN — 1 Sector Write-Erase per bit starting at address 0x0 of flash
  [15:0] DATA — 1 Sector Write Erase protection 1: prohibits write-erase, 0: allows
0x3014 SYSCTL_FRWPROTMAINDATA — 1KB sector based RW protection of first 4KB of data bank
  [7:0] DATA — Each 1KB is configured for protection with 2 bits: 00 - No protection - Both RW allowed 01 - Write protection - R only, no W 10 - Read-write protection - No R, No W 11 - Not used (No R, only W does not make sense)
0x3018 SYSCTL_FRXPROTMAIN_START reset 0x40 — Customer programmable RX firewall. Start and End are specified at 64B sector granularity. If Start == End, then one sector is RX protected If End == Start + 1, then two sectors are RX protected. And so on. If End < Start, then no address range is RX protected. HW will not check this. Since the start and end addresses are sector granularity, we do not need to store the 6 LSBs. Assuming a max protected range of 256KB, we will need only 12 higher order bits to be stored.
  [31:6] ADDR — Higher order bits of start of RX protected MAIN flash bank address (ignoring least 6 bits that are sector-specific).
0x301C SYSCTL_FRXPROTMAIN_END reset 0x1 — Customer programmable RX firewall. Start and End are specified at 64B sector granularity. If Start == End, then one sector is RX protected If End == Start + 1, then two sectors are RX protected. And so on. If End < Start, then no address range is RX protected. HW will not check this. Since the start and end addresses are sector granularity, we do not need to store the 10 LSBs. Assuming a max protected range of 256KB, we will need only 12 higher order bits to be stored.
  fields as SYSCTL_FRXPROTMAIN_START
0x3020 SYSCTL_FIPPROT_START reset 0x1 — Customer programmable IP prorection firewall. Start and End are specified at 1KB sector granularity. If Start == End, then one sector is IP protected If End == Start + 1, then two sectors are IP protected. And so on. If End < Start, then no address range is IP protected. Since the start and end addresses are sector granularity, we do not need to store the 10 LSBs. Assuming a max protected range of 256KB, we will need only 12 higher order bits to be stored.
  fields as SYSCTL_FRXPROTMAIN_START
0x3024 SYSCTL_FIPPROT_END reset 0x1 — Customer programmable IP prorection firewall. Start and End are specified at 64B sector granularity. If Start == End, then one sector is IP protected If End == Start + 1, then two sectors are IP protected. And so on. If End < Start, then no address range is IP protected. Since the start and end addresses are sector granularity, we do not need to store the 10 LSBs. Assuming a max protected range of 256KB, we will need only 12 higher order bits to be stored.
  fields as SYSCTL_FRXPROTMAIN_START
0x3038 SYSCTL_FLBANKSWP_POLICY wo — Bank Swap Policy
  [0] POLICY — Flash Bank Swap Policy Intent. CSC can configure this to indicate SWAP. By default, at BOOTRST, the system comes up as NO_SWAP. BOOTCODE could set the policy to SWAP (via a shadowed bit in TRIMCFG). If set to SWAP, then CSC can not un-set it. Writing 0 has no effect. However, it is possible that BOOTCODE did not set the POLICY to 1, and CSC sets it to 1.
    0=NO_EFFECT; 1=SWAP (Bank Swap)
0x303C SYSCTL_SECCFG_FLBANKSWAP — Flash Bank Swap
  fields as SYSCTL_SOCLOCK_FLBANKSWAP
0x3044 SYSCTL_FWENABLE wo reset not defined — Firewall lock enable register
  [all] fields
    0=NO_EFFECT; 1=ENABLE
  [8] SRAMBOUNDARY_LOCK — SRAM Boundary Lock set 0 -- > Leave Boundary MMR writeable post INITDONE 1 -- > Lock Boundary from being written post INITDONE
  [6] FLIPPROT
  [4] FLRXPROT
0x3048 SYSCTL_SECSTAT ro reset not defined — Firewall status register
  [10] FLBANK_SWAP
    1=YES (System has a CSC.); 2=NO (No, system does not have a CSC)
  [8] SRBNDRY_LOCK — SRAM Boundary Lock. 0 -- > not locked, 1 -- > locked
    0=DISABLED; 1=ENABLED
  [6] FLIPPROT_VALID — Firewall validity. 0 -- > not valid, 1 -- > valid
    0=DISABLED; 1=ENABLED
  [4] FLRXPROT_VALID — Firewall validity. 0 -- > not valid, 1 -- > valid
    0=DISABLED; 1=ENABLED
  [2] CSC_EXISTS
    0=NO (No, system does not have a CSC); 1=YES (System has a CSC.)
  [0] INITDONE
    0=NO (INIT is not yet done); 1=YES (INIT is Done)
0x304C SYSCTL_APSTART reset 0x4 — Application Reset Handler address
  [21:2] ADDR
0x3050 SYSCTL_APPSP — Application Stack Pointer
  [19:0] ADDR
0x3060 SYSCTL_INITDONE wo (reset mask 0xFF000001) — INITDONE PASS
  [1:0] PASS — Customer Startup Code writes 3 for PASS, No timeout enforcement.
    0=NO_EFFECT; 3=TRUE (BOOTCODE PASS)
